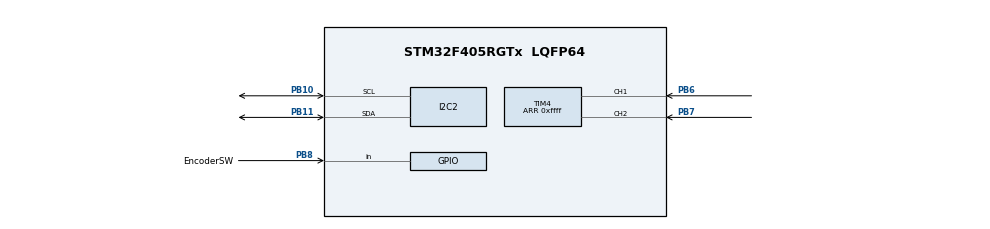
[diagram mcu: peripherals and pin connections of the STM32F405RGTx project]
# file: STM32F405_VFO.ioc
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Mcu.Family=STM32F4
Mcu.Name=STM32F405RGTx
Mcu.Package=LQFP64
NVIC.PriorityGroup=NVIC_PRIORITYGROUP_4
PA13.Mode=JTAG_5_pins
PA13.Signal=SYS_JTMS-SWDIO
PA14.Mode=JTAG_5_pins
PA14.Signal=SYS_JTCK-SWCLK
PA15.Mode=JTAG_5_pins
PA15.Signal=SYS_JTDI
PB10.Mode=I2C
PB10.Signal=I2C2_SCL
PB11.Mode=I2C
PB11.Signal=I2C2_SDA
PB3.Mode=JTAG_5_pins
PB3.Signal=SYS_JTDO-SWO
PB4.Mode=JTAG_5_pins
PB4.Signal=SYS_JTRST
PB6.GPIO_PuPd=GPIO_PULLUP
PB6.Signal=S_TIM4_CH1
PB7.GPIO_PuPd=GPIO_PULLUP
PB7.Signal=S_TIM4_CH2
PB8.GPIO_Label=EncoderSW
PB8.Signal=GPIO_Input
PH0-OSC_IN.Mode=HSE-External-Oscillator
PH0-OSC_IN.Signal=RCC_OSC_IN
PH1-OSC_OUT.Mode=HSE-External-Oscillator
PH1-OSC_OUT.Signal=RCC_OSC_OUT
ProjectManager.HeapSize=0x200
ProjectManager.StackSize=0x400
ProjectManager.TargetToolchain=TrueSTUDIO
RCC.48MHZClocksFreq_Value=48000000
RCC.AHBFreq_Value=168000000
RCC.APB1CLKDivider=RCC_HCLK_DIV4
RCC.APB1Freq_Value=42000000
RCC.APB1TimFreq_Value=84000000
RCC.APB2CLKDivider=RCC_HCLK_DIV2
RCC.APB2Freq_Value=84000000
RCC.APB2TimFreq_Value=168000000
RCC.CortexFreq_Value=168000000
RCC.HCLKFreq_Value=168000000
RCC.HSE_VALUE=8000000
RCC.HSI_VALUE=16000000
RCC.LSE_VALUE=32768
RCC.PLLM=4
RCC.PLLN=168
RCC.PLLQ=7
RCC.PLLSourceVirtual=RCC_PLLSOURCE_HSE
RCC.SYSCLKFreq_VALUE=168000000
RCC.SYSCLKSource=RCC_SYSCLKSOURCE_PLLCLK
RCC.VCOOutputFreq_Value=336000000
SH.S_TIM4_CH1.0=TIM4_CH1,Encoder_Interface
SH.S_TIM4_CH2.0=TIM4_CH2,Encoder_Interface
TIM4.CounterMode=TIM_COUNTERMODE_UP
TIM4.EncoderMode=TIM_ENCODERMODE_TI12
TIM4.IC1Filter=8
TIM4.IC2Filter=8
TIM4.Period=0xffff
board=custom

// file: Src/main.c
/* USER CODE BEGIN Header */
/**
  ******************************************************************************
  * @file           : main.c
  * @brief          : Main program body
  ******************************************************************************
  * @attention
  *
  * <h2><center>&copy; Copyright (c) 2020 STMicroelectronics.
  * All rights reserved.</center></h2>
  *
  * This software component is licensed by ST under BSD 3-Clause license,
  * the "License"; You may not use this file except in compliance with the
  * License. You may obtain a copy of the License at:
  *                        opensource.org/licenses/BSD-3-Clause
  *
  ******************************************************************************
  */
/* USER CODE END Header */

#include "main.h"

/* USER CODE BEGIN Includes */
#include "App.h"
/* USER CODE END Includes */

I2C_HandleTypeDef hi2c2;

TIM_HandleTypeDef htim4;

void SystemClock_Config(void);
static void MX_GPIO_Init(void);
static void MX_TIM4_Init(void);
static void MX_I2C2_Init(void);

int main(void)
{

  /* MCU Configuration--------------------------------------------------------*/

  /* Reset of all peripherals, Initializes the Flash interface and the Systick. */
  HAL_Init();

  /* Configure the system clock */
  SystemClock_Config();

  /* Initialize all configured peripherals */
  MX_GPIO_Init();
  MX_TIM4_Init();
  MX_I2C2_Init();
  /* USER CODE BEGIN 2 */
  LL_SYSTICK_EnableIT();
  HAL_TIM_Encoder_Start(&htim4,TIM_CHANNEL_ALL);

  /* USER CODE END 2 */

  /* Infinite loop */
  /* USER CODE BEGIN WHILE */
  TIM4->CNT = 0x3FFF; //set counter midpoint

  //char *str3 = "SingularEngineer";
  char *blank = "              ";
  LCD_Init();
  while(*blank)
	  LCD_Data(*blank++);

  while (1)
  {
	  MainApp();
    /* USER CODE END WHILE */

  }
}

void SystemClock_Config(void)
{
  LL_FLASH_SetLatency(LL_FLASH_LATENCY_5);

  if(LL_FLASH_GetLatency() != LL_FLASH_LATENCY_5)
  {
  Error_Handler();
  }
  LL_PWR_SetRegulVoltageScaling(LL_PWR_REGU_VOLTAGE_SCALE1);
  LL_RCC_HSE_Enable();

   /* Wait till HSE is ready */
  while(LL_RCC_HSE_IsReady() != 1)
  {

  }
  LL_RCC_PLL_ConfigDomain_SYS(LL_RCC_PLLSOURCE_HSE, LL_RCC_PLLM_DIV_4, 168, LL_RCC_PLLP_DIV_2);
  LL_RCC_PLL_Enable();

   /* Wait till PLL is ready */
  while(LL_RCC_PLL_IsReady() != 1)
  {

  }
  LL_RCC_SetAHBPrescaler(LL_RCC_SYSCLK_DIV_1);
  LL_RCC_SetAPB1Prescaler(LL_RCC_APB1_DIV_4);
  LL_RCC_SetAPB2Prescaler(LL_RCC_APB2_DIV_2);
  LL_RCC_SetSysClkSource(LL_RCC_SYS_CLKSOURCE_PLL);

   /* Wait till System clock is ready */
  while(LL_RCC_GetSysClkSource() != LL_RCC_SYS_CLKSOURCE_STATUS_PLL)
  {

  }
  LL_SetSystemCoreClock(168000000);

   /* Update the time base */
  if (HAL_InitTick (TICK_INT_PRIORITY) != HAL_OK)
  {
    Error_Handler();
  };
}

static void MX_I2C2_Init(void)
{

  hi2c2.Instance = I2C2;
  hi2c2.Init.ClockSpeed = 100000;
  hi2c2.Init.DutyCycle = I2C_DUTYCYCLE_2;
  hi2c2.Init.OwnAddress1 = 0;
  hi2c2.Init.AddressingMode = I2C_ADDRESSINGMODE_7BIT;
  hi2c2.Init.DualAddressMode = I2C_DUALADDRESS_DISABLE;
  hi2c2.Init.OwnAddress2 = 0;
  hi2c2.Init.GeneralCallMode = I2C_GENERALCALL_DISABLE;
  hi2c2.Init.NoStretchMode = I2C_NOSTRETCH_DISABLE;
  if (HAL_I2C_Init(&hi2c2) != HAL_OK)
  {
    Error_Handler();
  }

}

static void MX_TIM4_Init(void)
{

  TIM_Encoder_InitTypeDef sConfig = {0};
  TIM_MasterConfigTypeDef sMasterConfig = {0};

  htim4.Instance = TIM4;
  htim4.Init.Prescaler = 0;
  htim4.Init.CounterMode = TIM_COUNTERMODE_CENTERALIGNED2;
  htim4.Init.Period = 0xffff;
  htim4.Init.ClockDivision = TIM_CLOCKDIVISION_DIV1;
  htim4.Init.AutoReloadPreload = TIM_AUTORELOAD_PRELOAD_DISABLE;
  sConfig.EncoderMode = TIM_ENCODERMODE_TI12;
  sConfig.IC1Polarity = TIM_ICPOLARITY_RISING;
  sConfig.IC1Selection = TIM_ICSELECTION_DIRECTTI;
  sConfig.IC1Prescaler = TIM_ICPSC_DIV1;
  sConfig.IC1Filter = 8;
  sConfig.IC2Polarity = TIM_ICPOLARITY_RISING;
  sConfig.IC2Selection = TIM_ICSELECTION_DIRECTTI;
  sConfig.IC2Prescaler = TIM_ICPSC_DIV1;
  sConfig.IC2Filter = 8;
  if (HAL_TIM_Encoder_Init(&htim4, &sConfig) != HAL_OK)
  {
    Error_Handler();
  }
  sMasterConfig.MasterOutputTrigger = TIM_TRGO_RESET;
  sMasterConfig.MasterSlaveMode = TIM_MASTERSLAVEMODE_DISABLE;
  if (HAL_TIMEx_MasterConfigSynchronization(&htim4, &sMasterConfig) != HAL_OK)
  {
    Error_Handler();
  }

}

static void MX_GPIO_Init(void)
{
  LL_GPIO_InitTypeDef GPIO_InitStruct = {0};

  /* GPIO Ports Clock Enable */
  LL_AHB1_GRP1_EnableClock(LL_AHB1_GRP1_PERIPH_GPIOH);
  LL_AHB1_GRP1_EnableClock(LL_AHB1_GRP1_PERIPH_GPIOB);
  LL_AHB1_GRP1_EnableClock(LL_AHB1_GRP1_PERIPH_GPIOA);

  /**/
  GPIO_InitStruct.Pin = EncoderSW_Pin;
  GPIO_InitStruct.Mode = LL_GPIO_MODE_INPUT;
  GPIO_InitStruct.Pull = LL_GPIO_PULL_NO;
  LL_GPIO_Init(EncoderSW_GPIO_Port, &GPIO_InitStruct);

}

void Error_Handler(void)
{
}

/************************ (C) COPYRIGHT STMicroelectronics *****END OF FILE****/
